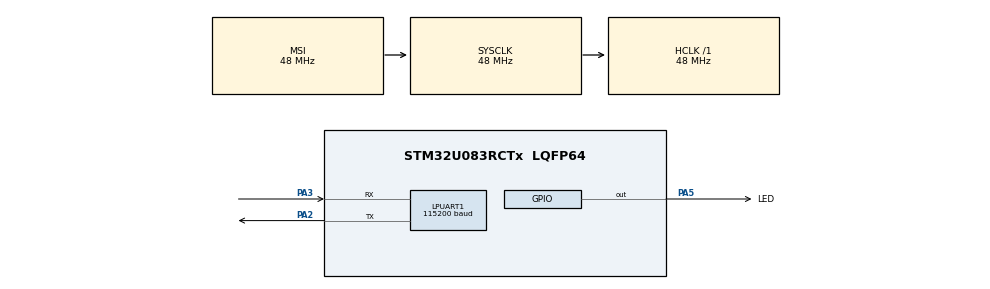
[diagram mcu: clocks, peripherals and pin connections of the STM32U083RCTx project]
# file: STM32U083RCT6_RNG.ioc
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Dma.LPUART1_RX.0.Direction=DMA_PERIPH_TO_MEMORY
Dma.LPUART1_RX.0.EventEnable=DISABLE
Dma.LPUART1_RX.0.Instance=DMA1_Channel1
Dma.LPUART1_RX.0.MemDataAlignment=DMA_MDATAALIGN_BYTE
Dma.LPUART1_RX.0.MemInc=DMA_MINC_ENABLE
Dma.LPUART1_RX.0.Mode=DMA_NORMAL
Dma.LPUART1_RX.0.PeriphDataAlignment=DMA_PDATAALIGN_BYTE
Dma.LPUART1_RX.0.PeriphInc=DMA_PINC_DISABLE
Dma.LPUART1_RX.0.Polarity=HAL_DMAMUX_REQ_GEN_RISING
Dma.LPUART1_RX.0.Priority=DMA_PRIORITY_LOW
Dma.LPUART1_RX.0.RequestNumber=1
Dma.LPUART1_RX.0.SignalID=NONE
Dma.LPUART1_RX.0.SyncEnable=DISABLE
Dma.LPUART1_RX.0.SyncPolarity=HAL_DMAMUX_SYNC_NO_EVENT
Dma.LPUART1_RX.0.SyncRequestNumber=1
Dma.LPUART1_RX.0.SyncSignalID=NONE
Dma.LPUART1_TX.1.Direction=DMA_MEMORY_TO_PERIPH
Dma.LPUART1_TX.1.EventEnable=DISABLE
Dma.LPUART1_TX.1.Instance=DMA1_Channel2
Dma.LPUART1_TX.1.MemDataAlignment=DMA_MDATAALIGN_BYTE
Dma.LPUART1_TX.1.MemInc=DMA_MINC_ENABLE
Dma.LPUART1_TX.1.Mode=DMA_NORMAL
Dma.LPUART1_TX.1.PeriphDataAlignment=DMA_PDATAALIGN_BYTE
Dma.LPUART1_TX.1.PeriphInc=DMA_PINC_DISABLE
Dma.LPUART1_TX.1.Polarity=HAL_DMAMUX_REQ_GEN_RISING
Dma.LPUART1_TX.1.Priority=DMA_PRIORITY_LOW
Dma.LPUART1_TX.1.RequestNumber=1
Dma.LPUART1_TX.1.SignalID=NONE
Dma.LPUART1_TX.1.SyncEnable=DISABLE
Dma.LPUART1_TX.1.SyncPolarity=HAL_DMAMUX_SYNC_NO_EVENT
Dma.LPUART1_TX.1.SyncRequestNumber=1
Dma.LPUART1_TX.1.SyncSignalID=NONE
Dma.Request0=LPUART1_RX
Dma.Request1=LPUART1_TX
LPUART1.BaudRate=115200
Mcu.Family=STM32U0
Mcu.Name=STM32U083RCTx
Mcu.Package=LQFP64
NVIC.DMA1_Channel1_IRQn=true\:0\:0\:false\:false\:true\:false\:true\:true
NVIC.DMA1_Channel2_3_IRQn=true\:0\:0\:false\:false\:true\:false\:true\:true
NVIC.PriorityGroup=NVIC_PRIORITYGROUP_2
NVIC.TIM1_BRK_UP_TRG_COM_IRQn=true\:0\:0\:false\:false\:true\:true\:true\:true
NVIC.USART3_LPUART1_IRQn=true\:0\:0\:false\:false\:true\:true\:true\:true
PA13\ (SWDIO).Mode=Serial_Wire
PA13\ (SWDIO).Signal=DEBUG_JTMS-SWDIO
PA14\ (SWCLK).Mode=Serial_Wire
PA14\ (SWCLK).Signal=DEBUG_JTCK-SWCLK
PA2.Mode=Asynchronous
PA2.Signal=LPUART1_TX
PA3.Mode=Asynchronous
PA3.Signal=LPUART1_RX
PA5.GPIO_Label=LED
PA5.GPIO_PuPd=GPIO_PULLUP
PA5.Signal=GPIO_Output
PC14-OSC32_IN.Mode=LSE-External-Oscillator
PC14-OSC32_IN.Signal=RCC_OSC32_IN
PC15-OSC32_OUT.Mode=LSE-External-Oscillator
PC15-OSC32_OUT.Signal=RCC_OSC32_OUT
PF0-OSC_IN.Mode=HSE-External-Oscillator
PF0-OSC_IN.Signal=RCC_OSC_IN
PF1-OSC_OUT.Mode=HSE-External-Oscillator
PF1-OSC_OUT.Signal=RCC_OSC_OUT
ProjectManager.HeapSize=0x200
ProjectManager.StackSize=0x400
ProjectManager.TargetToolchain=STM32CubeIDE
RCC.ADCFreq_Value=48000000
RCC.AHBFreq_Value=48000000
RCC.CortexFreq_Value=48000000
RCC.HCLKFreq_Value=48000000
RCC.HSE_VALUE=4000000
RCC.HSI48_VALUE=48000000
RCC.HSI_VALUE=16000000
RCC.MSIClockRangeVal=RCC_MSIRANGE_11
RCC.MSI_VALUE=48000000
RCC.PLLSourceVirtual=RCC_PLLSOURCE_HSE
RCC.SYSCLKFreq_VALUE=48000000
RCC.SYSCLKSource=RCC_SYSCLKSOURCE_MSI
RCC.USBFreq_Value=48000000
RCC.VCOOutputFreq_Value=16000000
TIM1.AutoReloadPreload=TIM_AUTORELOAD_PRELOAD_ENABLE
TIM1.Period=1000-1
TIM1.Prescaler=48-1
VP_PWR_VS_SECSignals.Mode=Security/Privilege
VP_RNG_VS_RNG.Mode=RNG_Activate
VP_TIM1_VS_ClockSourceINT.Mode=Internal
board=custom

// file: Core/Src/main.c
/* USER CODE BEGIN Header */
/**
  ******************************************************************************
  * @file           : main.c
  * @brief          : Main program body
  ******************************************************************************
  * @attention
  *
  * Copyright (c) 2024 STMicroelectronics.
  * All rights reserved.
  *
  * This software is licensed under terms that can be found in the LICENSE file
  * in the root directory of this software component.
  * If no LICENSE file comes with this software, it is provided AS-IS.
  *
  ******************************************************************************
  */
/* USER CODE END Header */
#include "main.h"
#include "dma.h"
#include "usart.h"
#include "rng.h"
#include "tim.h"
#include "gpio.h"

/* USER CODE BEGIN Includes */
volatile uint32_t sys_ms_timer = 0;
uint32_t task1 = 0;
/* USER CODE END Includes */

void SystemClock_Config(void);

/* USER CODE BEGIN 0 */
uint8_t task_scheduling(uint32_t *task, uint32_t time)
{
  if ((sys_ms_timer > *task) && ((sys_ms_timer - *task) > time))
  {
    *task = sys_ms_timer;
    return 1;
  }
  else if (*task > sys_ms_timer)
  {
    if (((0xffffffff - *task) + sys_ms_timer) > time)
    {
      *task = sys_ms_timer;
      return 1;
    }
  }
  return 0;
}

/* USER CODE END 0 */

int main(void)
{

  /* MCU Configuration--------------------------------------------------------*/

  /* Reset of all peripherals, Initializes the Flash interface and the Systick. */
  HAL_Init();

  /* Configure the system clock */
  SystemClock_Config();

  /* Initialize all configured peripherals */
  MX_GPIO_Init();
  MX_DMA_Init();
  MX_LPUART1_UART_Init();
  MX_TIM1_Init();
  MX_RNG_Init();
  /* USER CODE BEGIN 2 */

  EXTI->IMR1 |= 1<<0;
  HAL_NVIC_SetPriority(EXTI0_1_IRQn, 3, 0);
  HAL_NVIC_EnableIRQ(EXTI0_1_IRQn);

  __HAL_UART_ENABLE_IT(&hlpuart1, UART_IT_IDLE);
  HAL_UART_Receive_DMA(&hlpuart1,rx1_buffer,BUFFER_SIZE);
  HAL_TIM_Base_Start_IT(&htim1);
  /* USER CODE END 2 */

  /* Infinite loop */
  /* USER CODE BEGIN WHILE */
  uint32_t random = 0;
  uint8_t num[7] = {0};
  int i = 0;
  while (1)
  {
    if (task_scheduling(&task1, 500))
    {
      for (i = 0; i < 7; i++) {
        if (HAL_RNG_GenerateRandomNumber(&hrng, &random) != HAL_OK) {
          printf("error: generate ranom fail\n");
          i--;
        } else {
          num[i] = random % 33 + 1;
        }
      }

      if (HAL_RNG_GenerateRandomNumber(&hrng, &random) != HAL_OK) {
        printf("error: generate ranom fail\n");
      } else {
        num[6] = random % 16 + 1;
      }

      printf("生成的号码为: ");
      for (i = 0; i < 7; i++) {
        printf("%d ", (int)num[i]);
      }
      printf(" \n");

      HAL_GPIO_TogglePin(LED_GPIO_Port, LED_Pin);
    }

    /* USER CODE END WHILE */

  }
}

void SystemClock_Config(void)
{
  RCC_OscInitTypeDef RCC_OscInitStruct = {0};
  RCC_ClkInitTypeDef RCC_ClkInitStruct = {0};

  /** Configure the main internal regulator output voltage
  */
  HAL_PWREx_ControlVoltageScaling(PWR_REGULATOR_VOLTAGE_SCALE1);

  /** Initializes the RCC Oscillators according to the specified parameters
  * in the RCC_OscInitTypeDef structure.
  */
  RCC_OscInitStruct.OscillatorType = RCC_OSCILLATORTYPE_MSI;
  RCC_OscInitStruct.MSIState = RCC_MSI_ON;
  RCC_OscInitStruct.MSICalibrationValue = RCC_MSICALIBRATION_DEFAULT;
  RCC_OscInitStruct.MSIClockRange = RCC_MSIRANGE_11;
  RCC_OscInitStruct.PLL.PLLState = RCC_PLL_NONE;
  if (HAL_RCC_OscConfig(&RCC_OscInitStruct) != HAL_OK)
  {
    Error_Handler();
  }

  /** Initializes the CPU, AHB and APB buses clocks
  */
  RCC_ClkInitStruct.ClockType = RCC_CLOCKTYPE_HCLK|RCC_CLOCKTYPE_SYSCLK
                              |RCC_CLOCKTYPE_PCLK1;
  RCC_ClkInitStruct.SYSCLKSource = RCC_SYSCLKSOURCE_MSI;
  RCC_ClkInitStruct.AHBCLKDivider = RCC_SYSCLK_DIV1;
  RCC_ClkInitStruct.APB1CLKDivider = RCC_HCLK_DIV1;

  if (HAL_RCC_ClockConfig(&RCC_ClkInitStruct, FLASH_LATENCY_1) != HAL_OK)
  {
    Error_Handler();
  }
}

void Error_Handler(void)
{
  __disable_irq();
  while (1)
  {
  }
}
